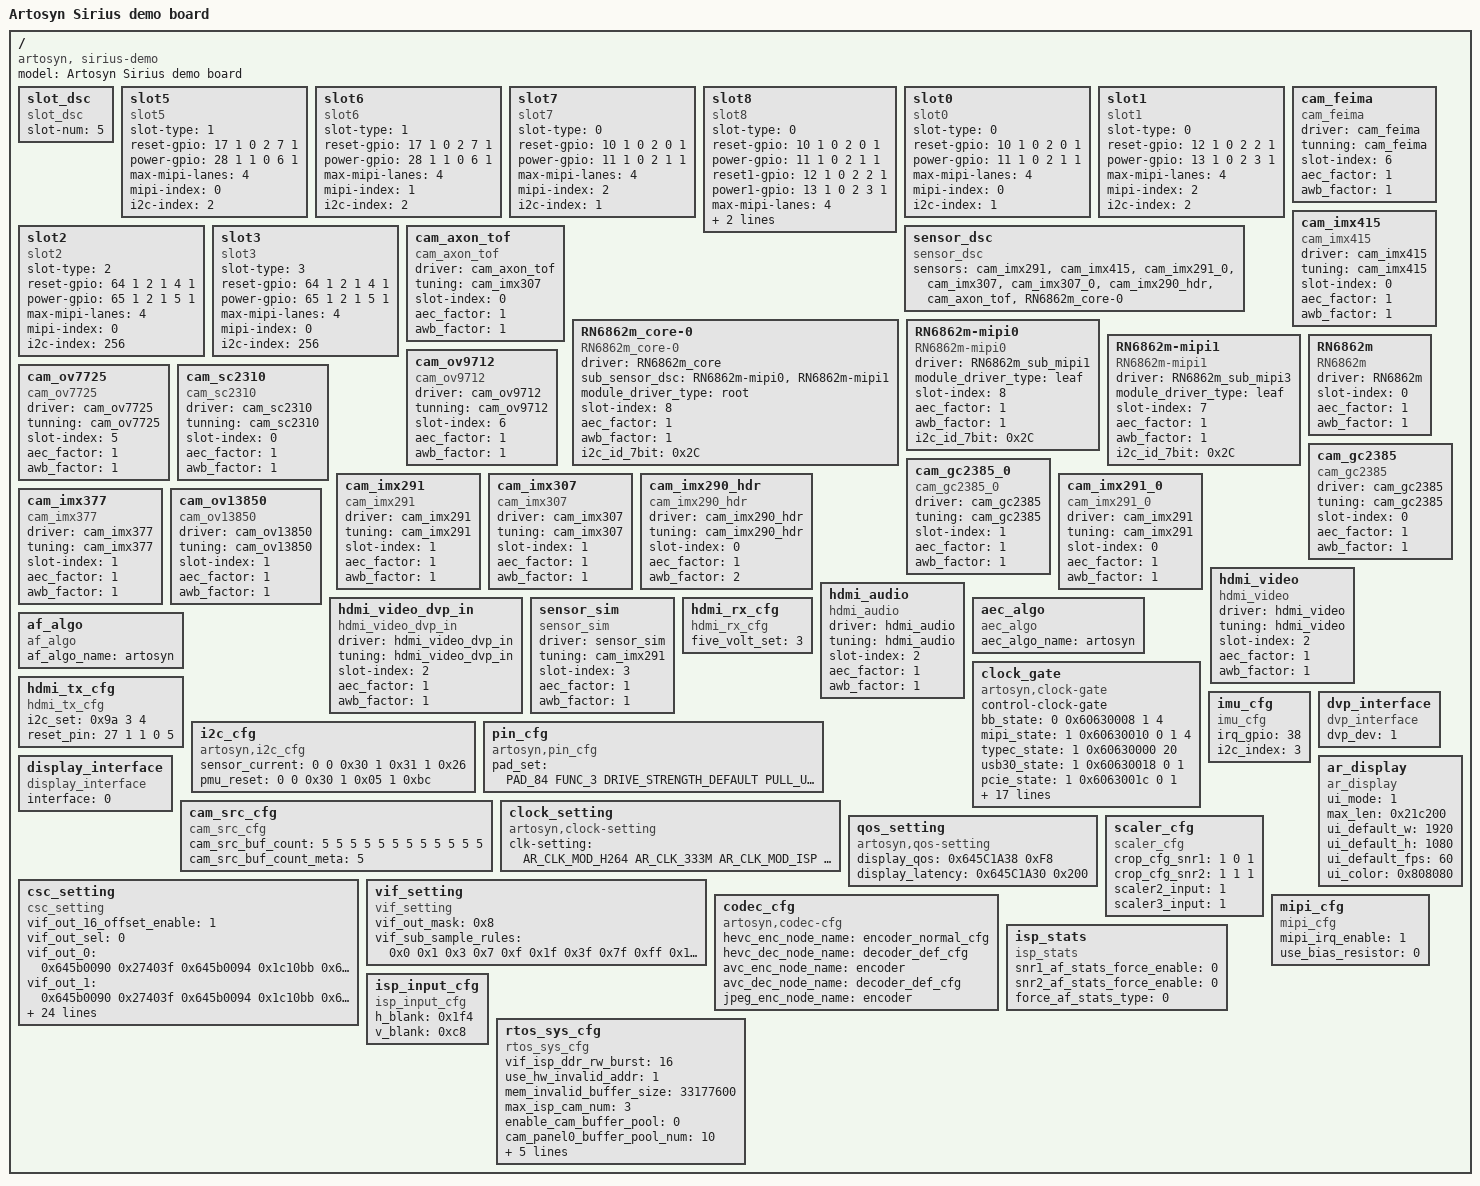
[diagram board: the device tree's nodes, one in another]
/*
 * Copyright 2015 Hans de Goede <hdegoede@redhat.com>
 *
 * Minimal dts file for the MSI Primo81 for u-boot only
 *
 * SPDX-License-Identifier:     GPL-2.0+ or X11
 */


/dts-v1/;
#include <ar_clk.h>
#include <ar_i2s.h>
#include <ar_pads.h>
/{
	model = "Artosyn Sirius demo board";
	compatible = "artosyn, sirius-demo";

	slot_dsc{
		compatible = "slot_dsc";
		slot-num = <5>;
	};

	slot5 {
		compatible = "slot5";
		slot-type = <1>;
		//padnum, gpio_function_num ,group, port,num,in_out
		reset-gpio = <17 1 0 2 7 1>;
        //dvp power not config
		power-gpio = <28 1 1 0 6 1>;
		//mipi lane num
		max-mipi-lanes = <4>;
        //dvp_index
		mipi-index = <0>;
		//i2c index
		i2c-index = <2>;

	};

	slot6 {
		compatible = "slot6";
		slot-type = <1>;
		//padnum, gpio_function_num ,group, port,num,in_out
		reset-gpio = <17 1 0 2 7 1>;
        //dvp power not config
		power-gpio = <28 1 1 0 6 1>;
		//mipi lane num
		max-mipi-lanes = <4>;
        //dvp_index
		mipi-index = <1>;
		//i2c index
		i2c-index = <2>;

	};

    slot7 {
        compatible = "slot7";
        slot-type = <0>;
        //padnum, gpio_function_num ,group, port,num,in_out
        reset-gpio = <10 1 0 2 0 1>;
        power-gpio = <11 1 0 2 1 1>;
        //mipi lane num
        max-mipi-lanes = <4>;
        mipi-index = <2>;
        //i2c index
        i2c-index = <1>;

    };

    slot8 {
        compatible = "slot8";
        slot-type = <0>;
        //padnum, gpio_function_num ,group, port,num,in_out
        reset-gpio = <10 1 0 2 0 1>;
        power-gpio = <11 1 0 2 1 1>;
        reset1-gpio = <12 1 0 2 2 1>;
        power1-gpio = <13 1 0 2 3 1>;
        //mipi lane num
        max-mipi-lanes = <4>;
        mipi-index = <0>;
        //i2c index
        i2c-index = <1>;

    };

	slot0 {
		compatible = "slot0";
		slot-type = <0>;
		//padnum, gpio_function_num ,group, port,num,in_out
		reset-gpio = <10 1 0 2 0 1>;
		power-gpio = <11 1 0 2 1 1>;
		//mipi lane num
		max-mipi-lanes = <4>;
		mipi-index = <0>;
		//i2c index
		i2c-index = <1>;

	};

	slot1 {
		compatible = "slot1";
		slot-type = <0>;
		//padnum, gpio_function_num ,group, port,num,in_out
		reset-gpio = <12 1 0 2 2 1>;
		power-gpio = <13 1 0 2 3 1>;
		//mipi lane num
		max-mipi-lanes = <4>;
		mipi-index = <2>;
		//i2c index
		i2c-index = <2>;

	};
	slot2 {
		compatible = "slot2";
		slot-type = <2>;
		//padnum, gpio_function_num ,group, port,num,in_out
		reset-gpio = <64 1 2 1 4 1>;
		power-gpio = <65 1 2 1 5 1>;
		//mipi lane num
		max-mipi-lanes = <4>;
		mipi-index = <0>;
		//i2c index
		i2c-index = <256>;

	};
	slot3 {
		compatible = "slot3";
		slot-type = <3>;
		//padnum, gpio_function_num ,group, port,num,in_out
		reset-gpio = <64 1 2 1 4 1>;
		power-gpio = <65 1 2 1 5 1>;
		//mipi lane num
		max-mipi-lanes = <4>;
		mipi-index = <0>;
		//i2c index
		i2c-index = <256>;

	};
	sensor_dsc{
		compatible = "sensor_dsc";
                //the sensor need to prob
		sensors ="cam_imx291" , "cam_imx415" , "cam_imx291_0", "cam_imx307" , "cam_imx307_0" , "cam_imx290_hdr", "cam_axon_tof" , "RN6862m_core-0";
	};
        //comatible will decidecd which driver will used
        //node will give the driver to creat sensor obj which name is it, and this name will decided which tuning header will
        //be used
    cam_feima{
        compatible = "cam_feima";
        driver       = "cam_feima";
        tunning      = "cam_feima";
        slot-index = <6>;
        aec_factor = <1>;
        awb_factor = <1>;
    };

    cam_imx415{
        compatible   = "cam_imx415";
        driver       = "cam_imx415";
        tuning       = "cam_imx415";
        slot-index   = <0>;
        aec_factor   = <1>;
        awb_factor   = <1>;
    };
    cam_axon_tof{
        compatible   = "cam_axon_tof";
        driver       = "cam_axon_tof";
        tuning       = "cam_imx307";
        slot-index   = <0>;
        aec_factor   = <1>;
        awb_factor   = <1>;
    };

    RN6862m_core-0{
        compatible = "RN6862m_core-0";
        driver       = "RN6862m_core";
        sub_sensor_dsc = "RN6862m-mipi0", "RN6862m-mipi1";
        module_driver_type = "root";
        slot-index = <8>;
        aec_factor = <1>;
        awb_factor = <1>;
        i2c_id_7bit = <0x2C>;
    };
    RN6862m-mipi0{
        compatible = "RN6862m-mipi0";
        driver       = "RN6862m_sub_mipi1";
        module_driver_type = "leaf";
        slot-index = <8>;
        aec_factor = <1>;
        awb_factor = <1>;
        i2c_id_7bit = <0x2C>;
    };
    RN6862m-mipi1{
        compatible = "RN6862m-mipi1";
        driver       = "RN6862m_sub_mipi3";
        module_driver_type = "leaf";
        slot-index = <7>;
        aec_factor = <1>;
        awb_factor = <1>;
        i2c_id_7bit = <0x2C>;
    };

    RN6862m{
        compatible = "RN6862m";
        driver       = "RN6862m";
        slot-index = <0>;
        aec_factor = <1>;
        awb_factor = <1>;
    };

    cam_ov9712{
        compatible = "cam_ov9712";
        driver       = "cam_ov9712";
        tunning      = "cam_ov9712";
        slot-index = <6>;
        aec_factor = <1>;
        awb_factor = <1>;
    };
    cam_ov7725{
        compatible = "cam_ov7725";
        driver       = "cam_ov7725";
        tunning      = "cam_ov7725";
        slot-index = <5>;
        aec_factor = <1>;
        awb_factor = <1>;
    };
	cam_sc2310{
		compatible = "cam_sc2310";
                driver       = "cam_sc2310";
                tunning      = "cam_sc2310";
		slot-index = <0>;
		aec_factor = <1>;
		awb_factor = <1>;
	};

	cam_gc2385{
		compatible = "cam_gc2385";
                driver       = "cam_gc2385";
                tuning       = "cam_gc2385";
		slot-index = <0>;
		aec_factor = <1>;
		awb_factor = <1>;
	};
	cam_gc2385_0{
		compatible = "cam_gc2385_0";
                driver       = "cam_gc2385";
                tuning       = "cam_gc2385";
		slot-index = <1>;
		aec_factor = <1>;
		awb_factor = <1>;
	};
	cam_imx291{
		compatible = "cam_imx291";
                driver       = "cam_imx291";
                tuning       = "cam_imx291";
		slot-index = <1>;
		aec_factor = <1>;
		awb_factor = <1>;
	};
	cam_imx307{
		compatible = "cam_imx307";
                driver = "cam_imx307";
                tuning= "cam_imx307";
		slot-index = <1>;
		aec_factor = <1>;
		awb_factor = <1>;
	};
	cam_imx290_hdr{
		compatible = "cam_imx290_hdr";
                driver = "cam_imx290_hdr";
                tuning = "cam_imx290_hdr";
		slot-index = <0>;
		aec_factor = <1>;
		awb_factor = <2>;
	};
	cam_imx291_0{
		compatible = "cam_imx291_0";
                driver = "cam_imx291";
                tuning = "cam_imx291";
		slot-index = <0>;
		aec_factor = <1>;
		awb_factor = <1>;
		};
	cam_imx377{
		compatible = "cam_imx377";
                driver      = "cam_imx377";
                tuning     = "cam_imx377";
		slot-index = <1>;
		aec_factor = <1>;
		awb_factor = <1>;
	};
	cam_ov13850{
		compatible = "cam_ov13850";
                driver     = "cam_ov13850";
                tuning     = "cam_ov13850";
		slot-index = <1>;
		aec_factor = <1>;
		awb_factor = <1>;
	};
	hdmi_video{
		compatible = "hdmi_video";
                driver       = "hdmi_video";
                tuning      = "hdmi_video";
		slot-index = <2>;
		aec_factor = <1>;
		awb_factor = <1>;
	};
	hdmi_audio{
		compatible = "hdmi_audio";
                driver       = "hdmi_audio";
                tuning     = "hdmi_audio";
		slot-index = <2>;
		aec_factor = <1>;
		awb_factor = <1>;
	};
	hdmi_video_dvp_in{
		compatible = "hdmi_video_dvp_in";
                driver       =  "hdmi_video_dvp_in";
                tuning    = "hdmi_video_dvp_in";
		slot-index = <2>;
		aec_factor = <1>;
		awb_factor = <1>;
	};
       sensor_sim{
		compatible = "sensor_sim";
                driver = "sensor_sim";
                tuning = "cam_imx291";
		slot-index = <3>;
		aec_factor = <1>;
		awb_factor = <1>;
	};

    aec_algo{
        compatible = "aec_algo";
        aec_algo_name       = "artosyn";
    };

    af_algo{
        compatible = "af_algo";
        af_algo_name       = "artosyn";
    };

	clock_gate {
		compatible = "artosyn,clock-gate";
		control-clock-gate;

		bb_state     = <0 0x60630008 1 4>;
		mipi_state   = <1 0x60630010 0 1 4>;
		typec_state  = <1 0x60630000 20>;
		usb30_state  = <1 0x60630018 0 1>;
		pcie_state   = <1 0x6063001c 0 1>;
		m7_state     = <1 0x60630020 8 9 11>;
		gmac_state   = <1 0x60630030 0 1 3>;
		emmc_state   = <1 0x60630034 0 1 2>;
		dvprx_state  = <1 0x6063003c 0 1>;
		sram_state   = <1 0x60630040 0>;
		codec_state  = <0 0x60630004 0 1 2 3 8 9 10 19 27>;
		hdmirx_state = <0 0x6063000c 0 1 2 3>;
		sram_share_1 = <1 0x60634010 0>;	//sram share for ceva
		sram_share_0 = <0 0x60634010 17>;	//sram share for ceva

		SAR10_1_2_state = <1 0x60680380 0 1>;
                QDAC_IDAC_state = <1 0x60680384 21 22>;
                QDAC_IDAC2_state = <1 0x60680388 13 14>;
                adc_dac_state   = <1 0x6068038c 0 1 2 3 4 5 30 31>;
                ADCI_ADCQ_state  = <1 0x60680390 22 23>;
                ADCI_ADCQ2_state = <1 0x60680394 14 15>;
                ADCI_ADCQ3_state = <1 0x60680398 6 7>;
                SAR10_3_state   = <1 0x60632018 0>;

	};

	hdmi_tx_cfg {
		compatible = "hdmi_tx_cfg";
		//<i2c_component subaddr>
		i2c_set = <0x9a 3 4>;
		//<pad function group port gpio>
		reset_pin = <27 1 1 0 5>;
	};

	hdmi_rx_cfg {
                compatible = "hdmi_rx_cfg";
                //<hdmi_rx_five_volt_sense_gpio>
                five_volt_set = <3>;
        };

	i2c_cfg {
		compatible = "artosyn,i2c_cfg";
		//<i2c-num  read-write chip_addr addr_len register_addr byte_len byte ....>
		sensor_current = <0 0 0x30 1 0x31 1 0x26>;
		pmu_reset	   = <0 0 0x30 1 0x05 1 0xbc>;
	};

	pin_cfg {
                compatible = "artosyn,pin_cfg";
                pad_set  = <
				//pin_share_typec
				PAD_84	FUNC_3	DRIVE_STRENGTH_DEFAULT PULL_UP_OR_DOWN_DEFAULT VALUE_DEFAULT
				PAD_85	FUNC_3	DRIVE_STRENGTH_DEFAULT PULL_UP_OR_DOWN_DEFAULT VALUE_DEFAULT
				PAD_86	FUNC_3	DRIVE_STRENGTH_DEFAULT PULL_UP_OR_DOWN_DEFAULT VALUE_DEFAULT
				PAD_87	FUNC_3	DRIVE_STRENGTH_DEFAULT PULL_UP_OR_DOWN_DEFAULT VALUE_DEFAULT
				PAD_88	FUNC_1	DRIVE_STRENGTH_DEFAULT PULL_UP_OR_DOWN_DEFAULT VALUE_DEFAULT
				PAD_89	FUNC_1	DRIVE_STRENGTH_DEFAULT PULL_UP_OR_DOWN_DEFAULT VALUE_DEFAULT
				PAD_90	FUNC_3	DRIVE_STRENGTH_DEFAULT PULL_UP_OR_DOWN_DEFAULT VALUE_DEFAULT
				PAD_91	FUNC_3	DRIVE_STRENGTH_DEFAULT PULL_UP_OR_DOWN_DEFAULT VALUE_DEFAULT
				PAD_92	FUNC_3	DRIVE_STRENGTH_DEFAULT PULL_UP_OR_DOWN_DEFAULT VALUE_DEFAULT
				PAD_93	FUNC_3	DRIVE_STRENGTH_DEFAULT PULL_UP_OR_DOWN_DEFAULT VALUE_DEFAULT
				PAD_94	FUNC_3	DRIVE_STRENGTH_DEFAULT PULL_UP_OR_DOWN_DEFAULT VALUE_DEFAULT
				PAD_95	FUNC_3	DRIVE_STRENGTH_DEFAULT PULL_UP_OR_DOWN_DEFAULT VALUE_DEFAULT
				//pin_share_qspi
				PAD_76	FUNC_1	DRIVE_STRENGTH_DEFAULT PULL_UP_OR_DOWN_DEFAULT VALUE_DEFAULT
				PAD_77	FUNC_1	DRIVE_STRENGTH_DEFAULT PULL_UP_OR_DOWN_DEFAULT VALUE_DEFAULT
				PAD_78	FUNC_1	DRIVE_STRENGTH_DEFAULT PULL_UP_OR_DOWN_DEFAULT VALUE_DEFAULT
				PAD_79	FUNC_1	DRIVE_STRENGTH_DEFAULT PULL_UP_OR_DOWN_DEFAULT VALUE_DEFAULT
				PAD_80	FUNC_1	DRIVE_STRENGTH_DEFAULT PULL_UP_OR_DOWN_DEFAULT VALUE_DEFAULT
				PAD_81	FUNC_1	DRIVE_STRENGTH_DEFAULT PULL_UP_OR_DOWN_DEFAULT VALUE_DEFAULT
				PAD_82	FUNC_1	DRIVE_STRENGTH_DEFAULT PULL_UP_OR_DOWN_DEFAULT VALUE_DEFAULT
				PAD_83	FUNC_1	DRIVE_STRENGTH_DEFAULT PULL_UP_OR_DOWN_DEFAULT VALUE_DEFAULT
				PAD_121 FUNC_0	DRIVE_STRENGTH_DEFAULT PULL_UP_OR_DOWN_DEFAULT VALUE_DEFAULT
				PAD_122 FUNC_0	DRIVE_STRENGTH_DEFAULT PULL_UP_OR_DOWN_DEFAULT VALUE_DEFAULT
				PAD_123 FUNC_0	DRIVE_STRENGTH_DEFAULT PULL_UP_OR_DOWN_DEFAULT VALUE_DEFAULT
				PAD_124 FUNC_0	DRIVE_STRENGTH_DEFAULT PULL_UP_OR_DOWN_DEFAULT VALUE_DEFAULT
				PAD_125 FUNC_0	DRIVE_STRENGTH_DEFAULT PULL_UP_OR_DOWN_DEFAULT VALUE_DEFAULT
				PAD_126 FUNC_0	DRIVE_STRENGTH_DEFAULT PULL_UP_OR_DOWN_DEFAULT VALUE_DEFAULT
				PAD_127 FUNC_0	DRIVE_STRENGTH_DEFAULT PULL_UP_OR_DOWN_DEFAULT VALUE_DEFAULT
				PAD_128 FUNC_0	DRIVE_STRENGTH_DEFAULT PULL_UP_OR_DOWN_DEFAULT VALUE_DEFAULT
				PAD_129 FUNC_0	DRIVE_STRENGTH_DEFAULT PULL_UP_OR_DOWN_DEFAULT VALUE_DEFAULT
				PAD_130 FUNC_0	DRIVE_STRENGTH_DEFAULT PULL_UP_OR_DOWN_DEFAULT VALUE_DEFAULT
				PAD_131 FUNC_0	DRIVE_STRENGTH_DEFAULT PULL_UP_OR_DOWN_DEFAULT VALUE_DEFAULT
				PAD_132 FUNC_0	DRIVE_STRENGTH_DEFAULT PULL_UP_OR_DOWN_DEFAULT VALUE_DEFAULT
				PAD_133 FUNC_0	DRIVE_STRENGTH_DEFAULT PULL_UP_OR_DOWN_DEFAULT VALUE_DEFAULT
				PAD_134 FUNC_0	DRIVE_STRENGTH_DEFAULT PULL_UP_OR_DOWN_DEFAULT VALUE_DEFAULT
				PAD_135 FUNC_0	DRIVE_STRENGTH_DEFAULT PULL_UP_OR_DOWN_DEFAULT VALUE_DEFAULT
				PAD_136 FUNC_0	DRIVE_STRENGTH_DEFAULT PULL_UP_OR_DOWN_DEFAULT VALUE_DEFAULT
				PAD_137 FUNC_0	DRIVE_STRENGTH_DEFAULT PULL_UP_OR_DOWN_DEFAULT VALUE_DEFAULT
				//pin_share_i2s_master1
				PAD_64	FUNC_0	DRIVE_STRENGTH_DEFAULT PULL_UP_OR_DOWN_DEFAULT VALUE_DEFAULT
				PAD_65	FUNC_0	DRIVE_STRENGTH_DEFAULT PULL_UP_OR_DOWN_DEFAULT VALUE_DEFAULT
				PAD_66	FUNC_0	DRIVE_STRENGTH_DEFAULT PULL_UP_OR_DOWN_DEFAULT VALUE_DEFAULT
				PAD_67	FUNC_0	DRIVE_STRENGTH_DEFAULT PULL_UP_OR_DOWN_DEFAULT VALUE_DEFAULT
				//pin_share_bb_spi
				PAD_6	FUNC_4	DRIVE_STRENGTH_DEFAULT PULL_UP_OR_DOWN_DEFAULT VALUE_DEFAULT
				PAD_7	FUNC_4	DRIVE_STRENGTH_DEFAULT PULL_UP_OR_DOWN_DEFAULT VALUE_DEFAULT
				PAD_8	FUNC_4	DRIVE_STRENGTH_DEFAULT PULL_UP_OR_DOWN_DEFAULT VALUE_DEFAULT
				PAD_9	FUNC_4	DRIVE_STRENGTH_DEFAULT PULL_UP_OR_DOWN_DEFAULT VALUE_DEFAULT
				PAD_18	FUNC_2	DRIVE_STRENGTH_DEFAULT PULL_UP_OR_DOWN_DEFAULT VALUE_DEFAULT
				PAD_19	FUNC_2	DRIVE_STRENGTH_DEFAULT PULL_UP_OR_DOWN_DEFAULT VALUE_DEFAULT
				PAD_20	FUNC_2	DRIVE_STRENGTH_DEFAULT PULL_UP_OR_DOWN_DEFAULT VALUE_DEFAULT
				PAD_21	FUNC_2	DRIVE_STRENGTH_DEFAULT PULL_UP_OR_DOWN_DEFAULT VALUE_DEFAULT
				PAD_26	FUNC_0	DRIVE_STRENGTH_DEFAULT PULL_UP_OR_DOWN_DEFAULT VALUE_DEFAULT
				PAD_27	FUNC_1	DRIVE_STRENGTH_DEFAULT PULL_UP_OR_DOWN_DEFAULT VALUE_DEFAULT
				PAD_28	FUNC_1	DRIVE_STRENGTH_DEFAULT PULL_UP_OR_DOWN_DEFAULT VALUE_DEFAULT
				PAD_29	FUNC_0	DRIVE_STRENGTH_DEFAULT PULL_UP_OR_DOWN_DEFAULT VALUE_DEFAULT
				PAD_68	FUNC_4	DRIVE_STRENGTH_DEFAULT PULL_UP_OR_DOWN_DEFAULT VALUE_DEFAULT
				PAD_69	FUNC_4	DRIVE_STRENGTH_DEFAULT PULL_UP_OR_DOWN_DEFAULT VALUE_DEFAULT
				PAD_70	FUNC_4	DRIVE_STRENGTH_DEFAULT PULL_UP_OR_DOWN_DEFAULT VALUE_DEFAULT
				PAD_71	FUNC_4	DRIVE_STRENGTH_DEFAULT PULL_UP_OR_DOWN_DEFAULT VALUE_DEFAULT
				PAD_72	FUNC_4	DRIVE_STRENGTH_DEFAULT PULL_UP_OR_DOWN_DEFAULT VALUE_DEFAULT
				PAD_73	FUNC_4	DRIVE_STRENGTH_DEFAULT PULL_UP_OR_DOWN_DEFAULT VALUE_DEFAULT
				PAD_74	FUNC_4	DRIVE_STRENGTH_DEFAULT PULL_UP_OR_DOWN_DEFAULT VALUE_DEFAULT
				PAD_75	FUNC_4	DRIVE_STRENGTH_DEFAULT PULL_UP_OR_DOWN_DEFAULT VALUE_DEFAULT
				//pin_share_ceva_uart
				PAD_47	FUNC_3	DRIVE_STRENGTH_DEFAULT PULL_UP_OR_DOWN_DEFAULT VALUE_DEFAULT
				PAD_44	FUNC_0	DRIVE_STRENGTH_DEFAULT PULL_UP_OR_DOWN_DEFAULT VALUE_DEFAULT
				PAD_45	FUNC_0	DRIVE_STRENGTH_DEFAULT PULL_UP_OR_DOWN_DEFAULT VALUE_DEFAULT
				//[pin_share_dvp_data
				PAD_100 FUNC_4	DRIVE_STRENGTH_DEFAULT PULL_UP_OR_DOWN_DEFAULT VALUE_DEFAULT
				PAD_101 FUNC_4	DRIVE_STRENGTH_DEFAULT PULL_UP_OR_DOWN_DEFAULT VALUE_DEFAULT
				PAD_102 FUNC_4	DRIVE_STRENGTH_DEFAULT PULL_UP_OR_DOWN_DEFAULT VALUE_DEFAULT
				PAD_103 FUNC_4	DRIVE_STRENGTH_DEFAULT PULL_UP_OR_DOWN_DEFAULT VALUE_DEFAULT
				PAD_104 FUNC_4	DRIVE_STRENGTH_DEFAULT PULL_UP_OR_DOWN_DEFAULT VALUE_DEFAULT
				PAD_105 FUNC_4	DRIVE_STRENGTH_DEFAULT PULL_UP_OR_DOWN_DEFAULT VALUE_DEFAULT
				PAD_106 FUNC_4	DRIVE_STRENGTH_DEFAULT PULL_UP_OR_DOWN_DEFAULT VALUE_DEFAULT
				PAD_107 FUNC_4	DRIVE_STRENGTH_DEFAULT PULL_UP_OR_DOWN_DEFAULT VALUE_DEFAULT
				PAD_17	FUNC_1	DRIVE_STRENGTH_DEFAULT PULL_UP_OR_DOWN_DEFAULT VALUE_DEFAULT
				//pin_share_hdmi_tx
				PAD_27	FUNC_1	DRIVE_STRENGTH_DEFAULT PULL_UP_OR_DOWN_DEFAULT VALUE_DEFAULT
				PAD_9	FUNC_3	DRIVE_STRENGTH_DEFAULT PULL_UP_OR_DOWN_DEFAULT VALUE_DEFAULT
				PAD_8	FUNC_3	DRIVE_STRENGTH_DEFAULT PULL_UP_OR_DOWN_DEFAULT VALUE_DEFAULT
				//pin_share_hdmi_rx
				PAD_4	FUNC_1	DRIVE_STRENGTH_DEFAULT PULL_UP_OR_DOWN_DEFAULT VALUE_DEFAULT
				PAD_3	FUNC_0	DRIVE_STRENGTH_DEFAULT PULL_UP_OR_DOWN_DEFAULT VALUE_DEFAULT
				//pin_share_i2s1
				PAD_60	FUNC_0	DRIVE_STRENGTH_DEFAULT PULL_UP_OR_DOWN_DEFAULT VALUE_DEFAULT
				PAD_61	FUNC_0	DRIVE_STRENGTH_DEFAULT PULL_UP_OR_DOWN_DEFAULT VALUE_DEFAULT
				PAD_62	FUNC_0	DRIVE_STRENGTH_DEFAULT PULL_UP_OR_DOWN_DEFAULT VALUE_DEFAULT
				PAD_63	FUNC_0	DRIVE_STRENGTH_DEFAULT PULL_UP_OR_DOWN_DEFAULT VALUE_DEFAULT
				//pin_share_i2s2
				PAD_64	FUNC_0	DRIVE_STRENGTH_DEFAULT PULL_UP_OR_DOWN_DEFAULT VALUE_DEFAULT
				PAD_65	FUNC_0	DRIVE_STRENGTH_DEFAULT PULL_UP_OR_DOWN_DEFAULT VALUE_DEFAULT
				PAD_66	FUNC_0	DRIVE_STRENGTH_DEFAULT PULL_UP_OR_DOWN_DEFAULT VALUE_DEFAULT
				PAD_67	FUNC_0	DRIVE_STRENGTH_DEFAULT PULL_UP_OR_DOWN_DEFAULT VALUE_DEFAULT
				//pin_share_i2s3
				PAD_68	FUNC_0	DRIVE_STRENGTH_DEFAULT PULL_UP_OR_DOWN_DEFAULT VALUE_DEFAULT
				PAD_69	FUNC_0	DRIVE_STRENGTH_DEFAULT PULL_UP_OR_DOWN_DEFAULT VALUE_DEFAULT
				PAD_70	FUNC_0	DRIVE_STRENGTH_DEFAULT PULL_UP_OR_DOWN_DEFAULT VALUE_DEFAULT
				PAD_71	FUNC_0	DRIVE_STRENGTH_DEFAULT PULL_UP_OR_DOWN_DEFAULT VALUE_DEFAULT
				//pin_share_i2s4
				PAD_72	FUNC_0	DRIVE_STRENGTH_DEFAULT PULL_UP_OR_DOWN_DEFAULT VALUE_DEFAULT
				PAD_73	FUNC_0	DRIVE_STRENGTH_DEFAULT PULL_UP_OR_DOWN_DEFAULT VALUE_DEFAULT
				PAD_74	FUNC_0	DRIVE_STRENGTH_DEFAULT PULL_UP_OR_DOWN_DEFAULT VALUE_DEFAULT
				PAD_75	FUNC_0	DRIVE_STRENGTH_DEFAULT PULL_UP_OR_DOWN_DEFAULT VALUE_DEFAULT
				//pin_share_usb_oc
				PAD_119	FUNC_0	DRIVE_STRENGTH_1	PULL_UP_OR_DOWN_3 VALUE_DEFAULT>;
         };

        imu_cfg {
               compatible = "imu_cfg";
               irq_gpio = <38>;
               i2c_index = <3>;
        };

        display_interface{
		compatible = "display_interface";
                //dvp:0 dp:1 mipi:2
		interface  = <0>;
	};

	dvp_interface{
		compatible = "dvp_interface";
                //vga:0 hdmi:1 hx8264:2
		dvp_dev  = <1>;
	};

        cam_src_cfg{
                compatible = "cam_src_cfg";
                //stream index 0 --11
                //                   0 1 2 3 4 5 6 7 8 9 10 11
                cam_src_buf_count = <5 5 5 5 5 5 5 5 5 5 5  5>;
                cam_src_buf_count_meta = <5>;
       };

       ar_display{
              compatible = "ar_display";
              //0 normal mode .1 ui mode
              ui_mode = <1>;
              //for 4k, we
              max_len= <0x21c200>;
              ui_default_w=<1920>;
              ui_default_h=<1080>;
              ui_default_fps=<60>;
              ui_color = <0x808080>;
       };

	clock_setting {
		compatible = "artosyn,clock-setting";
		clk-setting = <
			AR_CLK_MOD_H264			AR_CLK_333M
			AR_CLK_MOD_ISP			AR_CLK_400M
			AR_CLK_MOD_HEVC_CORE	AR_CLK_300M
			AR_CLK_MOD_HEVC_BPU		AR_CLK_300M
			AR_CLK_MOD_VIF			AR_CLK_500M
            //AR_CLK_MOD_DISP         AR_CLK_500M
		>;
	};

	qos_setting {
		compatible = "artosyn,qos-setting";
		display_qos = <0x645C1A38 0xF8>;
		display_latency = <0x645C1A30 0x200>;
	};

       csc_setting{
               compatible = "csc_setting";
               vif_out_16_offset_enable = <1>;
               //0:601 full 1:601 limit 2:709 full 3:709 limit
               vif_out_sel = <0>;
               vif_out_0=<
                       0x645b0090 0x27403f
                       0x645b0094 0x1c10bb
                       0x645b0098 0xf99ea5
                       0x645b009C 0xe68fd8
                       0x645b00A0 0x0001c1
                       0x645b00A8 0xc0eb0eb0
                >;
                vif_out_1=<
                       0x645b0090 0x27403f
                       0x645b0094 0x1c10bb
                       0x645b0098 0xf99ea5
                       0x645b009C 0xe68fd8
                       0x645b00A0 0x0001c1
                       0x645b00A8 0xc0eb0eb0
                >;
               vif_out_2=<
                       0x645b0090 0x27403f
                       0x645b0094 0x1c10bb
                       0x645b0098 0xf99ea5
                       0x645b009C 0xe68fd8
                       0x645b00A0 0x0001c1
                       0x645b00A8 0xc0eb0eb0
                >;
               vif_out_3=<
                       0x645b0090 0x27403f
                       0x645b0094 0x1c10bb
                       0x645b0098 0xf99ea5
                       0x645b009C 0xe68fd8
                       0x645b00A0 0x0001c1
                       0x645b00A8 0xc0eb0eb0
                >;
                isp_out_sel=<0>;
                isp_out_0=<
                       0x64803c00 0x027400bb
                       0x64803c04 0x0040003f
                       0x64803c08 0x815b8068
                       0x64803c0c 0x020001c1
                       0x64803c10 0x819901c1
	               0x64803c14 0x02008029
                       0x64803c00 0x027400bb
                       0x64803c04 0x0040003f
                       0x64803c08 0x815b8068
                       0x64803c0c 0x020001c1
                       0x64803c10 0x819901c1
	               0x64803c14 0x02008029
                >;
                 isp_out_1=<
                       0x64803c00 0x027400bb
                       0x64803c04 0x0040003f
                       0x64803c08 0x815b8068
                       0x64803c0c 0x020001c1
                       0x64803c10 0x819901c1
	               0x64803c14 0x02008029
                       0x64803c00 0x027400bb
                       0x64803c04 0x0040003f
                       0x64803c08 0x815b8068
                       0x64803c0c 0x020001c1
                       0x64803c10 0x819901c1
	               0x64803c14 0x02008029
                >;
                  isp_out_2=<
                       0x64803c00 0x027400bb
                       0x64803c04 0x0040003f
                       0x64803c08 0x815b8068
                       0x64803c0c 0x020001c1
                       0x64803c10 0x819901c1
	               0x64803c14 0x02008029
                       0x64803c00 0x027400bb
                       0x64803c04 0x0040003f
                       0x64803c08 0x815b8068
                       0x64803c0c 0x020001c1
                       0x64803c10 0x819901c1
	               0x64803c14 0x02008029
                >;
                   isp_out_3=<
                       0x64803c00 0x027400bb
                       0x64803c04 0x0040003f
                       0x64803c08 0x815b8068
                       0x64803c0c 0x020001c1
                       0x64803c10 0x819901c1
	               0x64803c14 0x02008029
                       0x64803c00 0x027400bb
                       0x64803c04 0x0040003f
                       0x64803c08 0x815b8068
                       0x64803c0c 0x020001c1
                       0x64803c10 0x819901c1
	               0x64803c14 0x02008029
                >;
          dvp_out_16_offset_enable = <1>;
                dvp_out_sel = <0>;
                dvp_out_0=<
                       0x645b0160 0x2750bb
                       0x645b0164 0x1c203f
                       0x645b0168 0xfd7e67
                       0x645b016c 0xea6f99
                       0x645b0170 0x0001c2
                       0x645b00ac 0x90f0eb
                >;
             dvp_out_1=<
                       0x645b0160 0x2750bb
                       0x645b0164 0x1c203f
                       0x645b0168 0xfd7e67
                       0x645b016c 0xea6f99
                       0x645b0170 0x0001c2
                       0x645b00ac 0x90f0eb
                >;
             dvp_out_2=<
                       0x645b0160 0x2750bb
                       0x645b0164 0x1c203f
                       0x645b0168 0xfd7e67
                       0x645b016c 0xea6f99
                       0x645b0170 0x0001c2
                       0x645b00ac 0x90f0eb
                >;
             dvp_out_3=<
                       0x645b0160 0x2750bb
                       0x645b0164 0x1c203f
                       0x645b0168 0xfd7e67
                       0x645b016c 0xea6f99
                       0x645b0170 0x0001c2
                       0x645b00ac 0x90f0eb
                >;

                //<enable itu709/601 limit/full>
		//itu709/601 value==1 ->VIDMODE_ITU709
		//itu709/601 value==0 ->VIDMODE_ITU601
		//limit/full value==1 ->VIDMODE_16_235
		//limit/full value==0 ->VIDMODE_0_255
                hdmi_tx_colormodeset = <1 1 1>;
       };
       vif_setting{
                compatible = "vif_setting";
                vif_out_mask = <0x8>; //mask the out 3(view1)
                vif_sub_sample_rules = <0x0 0x1 0x3 0x7 0xf 0x1f 0x3f 0x7f 0xff 0x1ff 0x3ff 0x7ff 0xfff 0x1fff 0x3ffff 0x7ffff>;
       };
       scaler_cfg{
             compatible = "scaler_cfg";
             //scaler1 2 3
             crop_cfg_snr1=<1 0 1 >;
             crop_cfg_snr2=<1 1 1 >;
             //scaler2 input sel, 0, frome cnf in, 1 frome crop 1 in
             scaler2_input = <1>;
             //scaler2 input sel, 0, frome cnf in, 1 frome crop 1 in
             scaler3_input = <1>;
       };

       codec_cfg {
             compatible = "artosyn,codec-cfg";
             hevc_enc_node_name = "encoder_normal_cfg";
             hevc_dec_node_name = "decoder_def_cfg";
             avc_enc_node_name = "encoder";
             avc_dec_node_name = "decoder_def_cfg";
             jpeg_enc_node_name = "encoder";
       };
        isp_stats{
            compatible = "isp_stats";
            snr1_af_stats_force_enable = <0>;
            snr2_af_stats_force_enable = <0>;
            // 0 - use tuning param
            // 1 - AF_STATS_SHARPNES
            // 2 - AF_STATS_FIR
            // 4 - AF_STATS_IIR
            force_af_stats_type = <0>;
        };

       mipi_cfg{
            compatible = "mipi_cfg";
            //0 disable the mipi irq
            mipi_irq_enable = <1>;
            use_bias_resistor = <0>; 
       };

       isp_input_cfg{
            compatible = "isp_input_cfg";
            h_blank = <0x1f4>;
            v_blank = <0xc8>; 
       };

    rtos_sys_cfg{
        compatible = "rtos_sys_cfg";
        vif_isp_ddr_rw_burst = <16>;
        use_hw_invalid_addr = <1>;
        //3840*2160*2*2 -- dma buffer
        mem_invalid_buffer_size = <33177600>;
        max_isp_cam_num = <3>;
        enable_cam_buffer_pool = <0>;
        cam_panel0_buffer_pool_num=<10>;
        //2048*1080+512
        cam_panel0_buffer_pool_unit_size=<2212352>;
        cam_panel1_buffer_pool_num=<10>;
        //2048*1080/4+512
        cam_panel1_buffer_pool_unit_size=<2212352>;
        cam_panel2_buffer_pool_num=<11>;
        //2048*1080/4+512
        cam_panel2_buffer_pool_unit_size=<2212352>;
    };

 #if 0
	/* Verified on evb */
	i2s_cfg {
		compatible = "i2s-cfg";
		mode = <1>;
		/*
		 * clock is optional, if you don't configure ws clock,
		 * I think you will configure it somewhere else, hdmi
		 * driver for example.
		 */
		clock = <48000>;
		io_cfg = <0xfff8>;

		bus0 {
			compatible = "i2s-bus-0";
			device = <I2S_DEV_MST3>;

			txchannels {
				compatible = "txchannels";
				width = <16>;
				chbitmap = <0x1>;
			};

			audiodev0 {
				compatible = "audio-device-0";
				interface = <I2S_INTERFACE_ALC5621>;
				i2c_component = <3>;
			};

		};
	};
#endif
};
